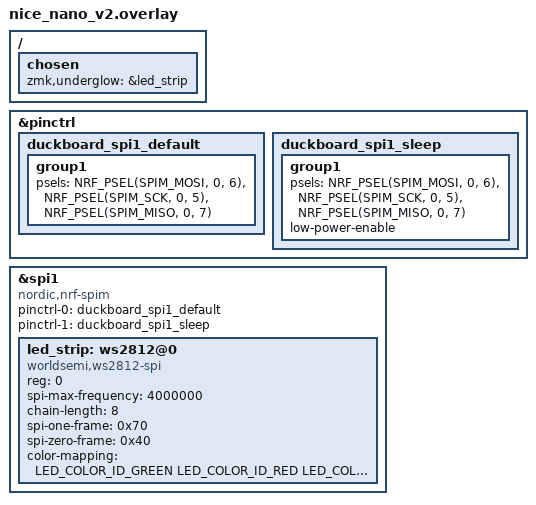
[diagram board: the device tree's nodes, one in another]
/* Copyright (c) 2020 The ZMK Contributors
 * SPDX-License-Identifier: MIT
 *
 * Author: Jack Hartstein
 */
#include <dt-bindings/led/led.h>
#include <dt-bindings/pinctrl/nrf-pinctrl.h>

&pinctrl {
    duckboard_spi1_default: duckboard_spi1_default {
        group1 {
            psels = <NRF_PSEL(SPIM_MOSI, 0, 6)>,
                    <NRF_PSEL(SPIM_SCK, 0, 5)>,
                    <NRF_PSEL(SPIM_MISO, 0, 7)>;
        };
    };

    duckboard_spi1_sleep: duckboard_spi1_sleep {
        group1 {
            psels = <NRF_PSEL(SPIM_MOSI, 0, 6)>,
                    <NRF_PSEL(SPIM_SCK, 0, 5)>,
                    <NRF_PSEL(SPIM_MISO, 0, 7)>;
            low-power-enable;
        };
    };
};

&spi1 {
    compatible = "nordic,nrf-spim";
    status = "okay";
    pinctrl-0 = <&duckboard_spi1_default>;
    pinctrl-1 = <&duckboard_spi1_sleep>;
    pinctrl-names = "default", "sleep";

    led_strip: ws2812@0 {
        compatible = "worldsemi,ws2812-spi";
        reg = <0>;
        spi-max-frequency = <4000000>;
        chain-length = <8>;
        spi-one-frame = <0x70>;
        spi-zero-frame = <0x40>;
        color-mapping = <LED_COLOR_ID_GREEN
                         LED_COLOR_ID_RED
                         LED_COLOR_ID_BLUE>;
    };
};

/ {
    chosen {
        zmk,underglow = &led_strip;
    };
};
